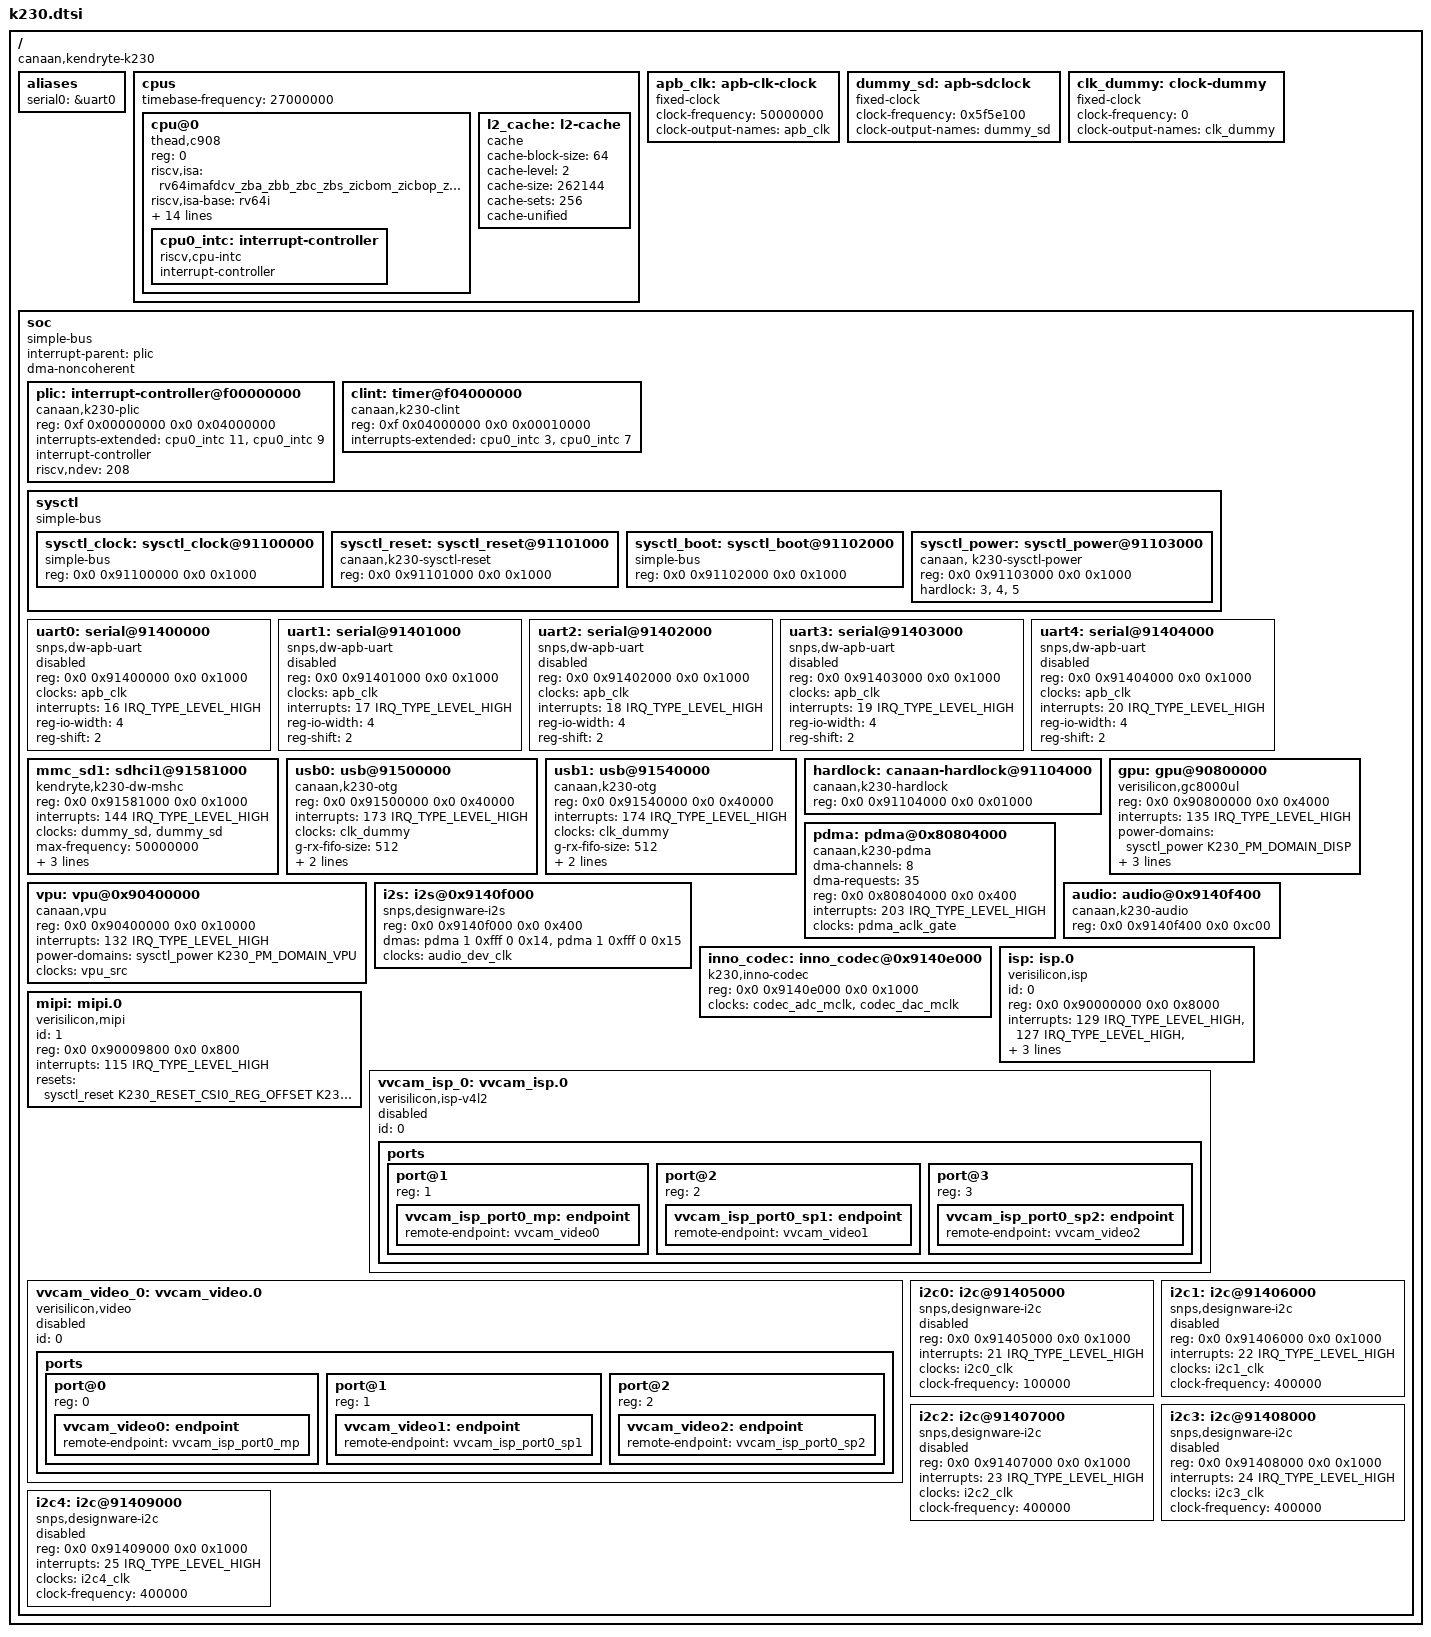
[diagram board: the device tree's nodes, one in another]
// SPDX-License-Identifier: GPL-2.0 OR MIT
/*
 * Copyright (C) 2024 Yangyu Chen <cyy@cyyself.name>
 */

#include <dt-bindings/interrupt-controller/irq.h>
#include <dt-bindings/soc/canaan,k230_pm_domains.h>
#include <dt-bindings/reset/canaan-k230-reset.h>

/dts-v1/;
/ {
	#address-cells = <2>;
	#size-cells = <2>;
	compatible = "canaan,kendryte-k230";

	aliases {
		serial0 = &uart0;
	};

	cpus {
		#address-cells = <1>;
		#size-cells = <0>;
		timebase-frequency = <27000000>;

		cpu@0 {
			compatible = "thead,c908", "riscv";
			device_type = "cpu";
			reg = <0>;
			riscv,isa = "rv64imafdcv_zba_zbb_zbc_zbs_zicbom_zicbop_zicboz_svpbmt";
			riscv,isa-base = "rv64i";
			riscv,isa-extensions = "i", "m", "a", "f", "d", "c", "v", "zba", "zbb",
					       "zbc", "zbs", "zicbom", "zicbop", "zicboz",
					       "zicntr", "zicsr", "zifencei", "zihpm", "svpbmt";
			riscv,cbom-block-size = <64>;
			riscv,cbop-block-size = <64>;
			riscv,cboz-block-size = <64>;
			d-cache-block-size = <64>;
			d-cache-sets = <128>;
			d-cache-size = <32768>;
			i-cache-block-size = <64>;
			i-cache-sets = <128>;
			i-cache-size = <32768>;
			next-level-cache = <&l2_cache>;
			mmu-type = "riscv,sv39";

			cpu0_intc: interrupt-controller {
				compatible = "riscv,cpu-intc";
				interrupt-controller;
				#interrupt-cells = <1>;
			};
		};

		l2_cache: l2-cache {
			compatible = "cache";
			cache-block-size = <64>;
			cache-level = <2>;
			cache-size = <262144>;
			cache-sets = <256>;
			cache-unified;
		};
	};

	apb_clk: apb-clk-clock {
		compatible = "fixed-clock";
		clock-frequency = <50000000>;
		clock-output-names = "apb_clk";
		#clock-cells = <0>;
	};
	dummy_sd:apb-sdclock {
		compatible = "fixed-clock";
		clock-frequency = <0x5f5e100>; //100M
		clock-output-names = "dummy_sd";
		#clock-cells = <0x00>;
	};
	clk_dummy: clock-dummy {
		compatible = "fixed-clock";
		clock-frequency = <0>;
		clock-output-names = "clk_dummy";
		#clock-cells = <0>;
	};

	soc {
		compatible = "simple-bus";
		interrupt-parent = <&plic>;
		#address-cells = <2>;
		#size-cells = <2>;
		dma-noncoherent;
		ranges;

		plic: interrupt-controller@f00000000 {
			compatible = "canaan,k230-plic" ,"thead,c900-plic";
			reg = <0xf 0x00000000 0x0 0x04000000>;
			interrupts-extended = <&cpu0_intc 11>, <&cpu0_intc 9>;
			interrupt-controller;
			#address-cells = <0>;
			#interrupt-cells = <2>;
			riscv,ndev = <208>;
		};

		clint: timer@f04000000 {
			compatible = "canaan,k230-clint", "thead,c900-clint";
			reg = <0xf 0x04000000 0x0 0x00010000>;
			interrupts-extended = <&cpu0_intc 3>, <&cpu0_intc 7>;
		};

		sysctl: sysctl {
			status					= "okay";
			#address-cells 			= <2>;
			#size-cells 			= <2>;
			compatible 				= "simple-bus";
			ranges;

			sysctl_clock: sysctl_clock@91100000 {
				status              = "okay";
				compatible 			= "simple-bus";
				reg                 = <0x0 0x91100000 0x0 0x1000>;
			};
			sysctl_reset: sysctl_reset@91101000 {
				status              = "okay";
				reg                 = <0x0 0x91101000 0x0 0x1000>;
				compatible      = "canaan,k230-sysctl-reset";
				#reset-cells    = <4>;     /* indicate consumer resets have 5 parameters. phandle+offset+type+done+assert */
			};
			sysctl_boot: sysctl_boot@91102000 {
				status              = "okay";
				compatible 			= "simple-bus";
				reg                 = <0x0 0x91102000 0x0 0x1000>;
			};
			sysctl_power: sysctl_power@91103000 {
				status              = "okay";
				reg                 = <0x0 0x91103000 0x0 0x1000>;
				compatible          = "canaan, k230-sysctl-power";
				hardlock            = <3>, <4>, <5>;
				#power-domain-cells = <1>;                          /* more than 1 power provider */
			};
		};

		uart0: serial@91400000 {
			compatible = "snps,dw-apb-uart";
			reg = <0x0 0x91400000 0x0 0x1000>;
			clocks = <&apb_clk>;
			interrupts = <16 IRQ_TYPE_LEVEL_HIGH>;
			reg-io-width = <4>;
			reg-shift = <2>;
			status = "disabled";
		};

		uart1: serial@91401000 {
			compatible = "snps,dw-apb-uart";
			reg = <0x0 0x91401000 0x0 0x1000>;
			clocks = <&apb_clk>;
			interrupts = <17 IRQ_TYPE_LEVEL_HIGH>;
			reg-io-width = <4>;
			reg-shift = <2>;
			status = "disabled";
		};

		uart2: serial@91402000 {
			compatible = "snps,dw-apb-uart";
			reg = <0x0 0x91402000 0x0 0x1000>;
			clocks = <&apb_clk>;
			interrupts = <18 IRQ_TYPE_LEVEL_HIGH>;
			reg-io-width = <4>;
			reg-shift = <2>;
			status = "disabled";
		};

		uart3: serial@91403000 {
			compatible = "snps,dw-apb-uart";
			reg = <0x0 0x91403000 0x0 0x1000>;
			clocks = <&apb_clk>;
			interrupts = <19 IRQ_TYPE_LEVEL_HIGH>;
			reg-io-width = <4>;
			reg-shift = <2>;
			status = "disabled";
		};

		uart4: serial@91404000 {
			compatible = "snps,dw-apb-uart";
			reg = <0x0 0x91404000 0x0 0x1000>;
			clocks = <&apb_clk>;
			interrupts = <20 IRQ_TYPE_LEVEL_HIGH>;
			reg-io-width = <4>;
			reg-shift = <2>;
			status = "disabled";
		};
		mmc_sd1: sdhci1@91581000 {
			compatible = "kendryte,k230-dw-mshc";
			reg = <0x0 0x91581000 0x0 0x1000>;
			interrupts = <144 IRQ_TYPE_LEVEL_HIGH>;
			interrupt-names = "sdhci1irq";
			clocks = <&dummy_sd>,<&dummy_sd>;
			clock-names = "core", "bus";
			max-frequency = <50000000>;
			bus-width = <4>;
			sdhci,auto-cmd12;
			dma-noncoherent;
			//status = "disabled";/*disabled, okay*/
			status = "okay";
		};
		usb0: usb@91500000 {
			compatible = "canaan,k230-otg", "snps,dwc2";
			reg = <0x0 0x91500000 0x0 0x40000>;
			interrupts = <173 IRQ_TYPE_LEVEL_HIGH>;
			clocks = <&clk_dummy>;
			clock-names = "otg";
			g-rx-fifo-size = <512>;
			g-np-tx-fifo-size = <64>;
			g-tx-fifo-size = <512 1024 64 64 64 64>;
		};

		usb1: usb@91540000 {
			compatible = "canaan,k230-otg", "snps,dwc2";
			reg = <0x0 0x91540000 0x0 0x40000>;
			interrupts = <174 IRQ_TYPE_LEVEL_HIGH>;
			clocks = <&clk_dummy>;
			clock-names = "otg";
			g-rx-fifo-size = <512>;
			g-np-tx-fifo-size = <64>;
			g-tx-fifo-size = <512 1024 64 64 64 64>;
		};

		hardlock: canaan-hardlock@91104000 {
			compatible = "canaan,k230-hardlock";
			reg = <0x0 0x91104000 0x0 0x01000>;
		};

		gpu: gpu@90800000 {
			compatible = "verisilicon,gc8000ul";
			reg = <0x0 0x90800000 0x0 0x4000>;
			interrupts = <135 IRQ_TYPE_LEVEL_HIGH>;
			power-domains = <&sysctl_power K230_PM_DOMAIN_DISP>;
			resets = <&sysctl_reset K230_RESET_V2P5D_REG_OFFSET K230_RESET_V2P5D_TYPE K230_RESET_V2P5D_DONE_BIT K230_RESET_V2P5D_ASSERT_BIT>;
			reset-names = "vglite";
			clocks = <&disp_gpu>;
			clock-names = "vglite";
			status = "okay";
		};

		vpu: vpu@0x90400000 {
			status              = "okay";
			compatible          = "canaan,vpu";
			reg                 = <0x0 0x90400000 0x0 0x10000>;
			interrupts          = <132 IRQ_TYPE_LEVEL_HIGH>;
			power-domains       = <&sysctl_power K230_PM_DOMAIN_VPU>;
			clocks              = <&vpu_src>;
            clock-names         = "vpu";
		};

		pdma: pdma@0x80804000 {
			#dma-cells          = <4>;
			dma-channels        = <8>;
			dma-requests        = <35>;
			status              = "okay";
			compatible          = "canaan,k230-pdma";
			reg                 = <0x0  0x80804000 0x0 0x400>;
			/*interrupt-parent    = <&intc>;*/
			interrupts          = <203 IRQ_TYPE_LEVEL_HIGH>;
			clocks              = <&pdma_aclk_gate>;
		};

		i2s: i2s@0x9140f000 {
			status              = "okay";
			compatible          = "snps,designware-i2s";
			reg                 = <0x0 0x9140f000 0x0 0x400>;
			dmas                = <&pdma 1 0xfff 0 0x14>, <&pdma 1 0xfff 0 0x15>;
			dma-names           = "tx", "rx";
			clocks              = <&audio_dev_clk>;
			clock-names         = "i2sclk";
		};

		/* audio */
		audio: audio@0x9140f400 {
			status              = "okay";
			compatible          = "canaan,k230-audio";
			reg                 = <0x0 0x9140f400 0x0 0xc00>;
		};

		inno_codec:inno_codec@0x9140e000{
			status              = "okay";
			compatible          = "k230,inno-codec";
			reg                 = <0x0 0x9140e000 0x0 0x1000>;
			clocks              = <&codec_adc_mclk>,<&codec_dac_mclk>;
			clock-names         = "adc", "dac";
		};


		isp: isp.0 {
			compatible = "verisilicon,isp";
			id = <0>;
			reg = <0x0 0x90000000 0x0 0x8000>;
			interrupts = <129 IRQ_TYPE_LEVEL_HIGH>, <127 IRQ_TYPE_LEVEL_HIGH>, <128 IRQ_TYPE_LEVEL_HIGH>;
			resets = <&sysctl_reset K230_RESET_ISP_REG_OFFSET K230_RESET_ISP_TYPE K230_RESET_ISP_DONE_BIT K230_RESET_ISP_ASSERT_BIT>;
			reset-names = "isp";
			status = "okay";
		};

		mipi: mipi.0 {
			compatible = "verisilicon,mipi";
			id = <1>;
			reg = <0x0 0x90009800 0x0 0x800>;
			interrupts = <115 IRQ_TYPE_LEVEL_HIGH>;
			resets = <&sysctl_reset K230_RESET_CSI0_REG_OFFSET K230_RESET_CSI0_TYPE K230_RESET_CSI0_DONE_BIT K230_RESET_CSI0_ASSERT_BIT>;
			reset-names = "mipi";
			status = "okay";
		};

		vvcam_isp_0: vvcam_isp.0 {
			compatible = "verisilicon,isp-v4l2";
			status = "disabled";
			id = <0>;
			ports {
				#address-cells = <1>;
				#size-cells = <0>;
				port@1 {
					reg = <1>;
					vvcam_isp_port0_mp: endpoint {
						remote-endpoint = <&vvcam_video0>;
					};
				};
				port@2 {
					reg = <2>;
					vvcam_isp_port0_sp1: endpoint {
						remote-endpoint = <&vvcam_video1>;
					};
				};
				port@3 {
					reg = <3>;
					vvcam_isp_port0_sp2: endpoint {
						remote-endpoint = <&vvcam_video2>;
					};
				};
			};
		};

		vvcam_video_0: vvcam_video.0 {
			compatible = "verisilicon,video";
			id = <0>;
			status = "disabled";

			ports {
				#address-cells = <1>;
				#size-cells = <0>;
				port@0 {
					reg = <0>;
					vvcam_video0: endpoint {
						remote-endpoint = <&vvcam_isp_port0_mp>;
					};
				};
				port@1 {
					reg = <1>;
					vvcam_video1: endpoint {
						remote-endpoint = <&vvcam_isp_port0_sp1>;
					};
				};
				port@2 {
					reg = <2>;
					vvcam_video2: endpoint {
						remote-endpoint = <&vvcam_isp_port0_sp2>;
					};
				};
			};
		};

		i2c0: i2c@91405000 {
			#address-cells = <1>;
			#size-cells = <0>;
			compatible = "snps,designware-i2c";
			reg = <0x0 0x91405000 0x0 0x1000>;
			interrupts = <21 IRQ_TYPE_LEVEL_HIGH>;
			clocks = <&i2c0_clk>;
			clock-frequency = <100000>;
			status = "disabled";
		};

		i2c1: i2c@91406000 {
			#address-cells = <1>;
			#size-cells = <0>;
			compatible = "snps,designware-i2c";
			reg = <0x0 0x91406000 0x0 0x1000>;
			interrupts = <22 IRQ_TYPE_LEVEL_HIGH>;
			clocks = <&i2c1_clk>;
			clock-frequency = <400000>;
			status = "disabled";
		};

		i2c2: i2c@91407000 {
			#address-cells = <1>;
			#size-cells = <0>;
			compatible = "snps,designware-i2c";
			reg = <0x0 0x91407000 0x0 0x1000>;
			interrupts = <23 IRQ_TYPE_LEVEL_HIGH>;
			clocks = <&i2c2_clk>;
			clock-frequency = <400000>;
			status = "disabled";
		};

		i2c3: i2c@91408000 {
			#address-cells = <1>;
			#size-cells = <0>;
			compatible = "snps,designware-i2c";
			reg = <0x0 0x91408000 0x0 0x1000>;
			interrupts = <24 IRQ_TYPE_LEVEL_HIGH>;
			clocks = <&i2c3_clk>;
			clock-frequency = <400000>;
			status = "disabled";
		};

		i2c4: i2c@91409000 {
			#address-cells = <1>;
			#size-cells = <0>;
			compatible = "snps,designware-i2c";
			reg = <0x0 0x91409000 0x0 0x1000>;
			interrupts = <25 IRQ_TYPE_LEVEL_HIGH>;
			clocks = <&i2c4_clk>;
			clock-frequency = <400000>;
			status = "disabled";
		};
	};
};

#include "k230_clock_provider.dtsi"
